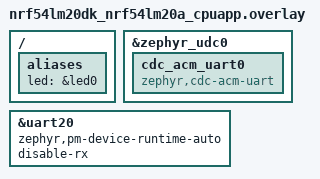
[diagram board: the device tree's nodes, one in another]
/*
 * Copyright (c) 2025 Nordic Semiconductor ASA
 *
 * SPDX-License-Identifier: LicenseRef-Nordic-5-Clause
 */

/ {
	aliases {
		led = &led0;
	};
};

&zephyr_udc0 {
	cdc_acm_uart0 {
		compatible = "zephyr,cdc-acm-uart";
	};
};

&uart20 {
	zephyr,pm-device-runtime-auto;
	disable-rx;
};
